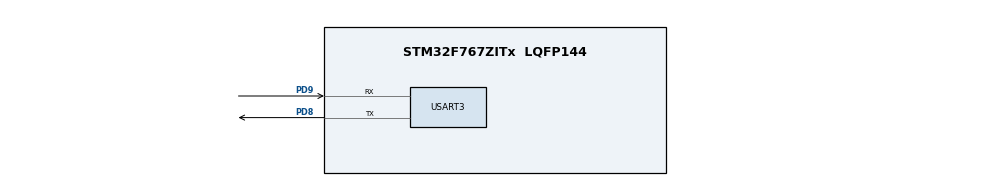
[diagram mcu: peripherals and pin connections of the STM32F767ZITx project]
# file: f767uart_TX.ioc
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Mcu.Family=STM32F7
PD9.Signal=USART3_RX
PD9.Mode=Asynchronous
ProjectManager.StackSize=0x400
USART3.VirtualMode-Asynchronous=VM_ASYNC
PA13.Signal=SYS_JTMS-SWDIO
ProjectManager.TargetToolchain=STM32CubeIDE
PD8.Signal=USART3_TX
RCC.USBFreq_Value=96000000
RCC.LSE_VALUE=32768
PD8.Mode=Asynchronous
RCC.HSE_VALUE=25000000
board=custom
RCC.VCOOutputFreq_Value=192000000
PA14.Mode=Serial_Wire
VP_SYS_VS_tim1.Mode=TIM1
PA13.Mode=Serial_Wire
Mcu.Name=STM32F767ZITx
Mcu.Package=LQFP144
NVIC.TimeBase=TIM1_UP_TIM10_IRQn
NVIC.TimeBaseIP=TIM1
PA14.Signal=SYS_JTCK-SWCLK
ProjectManager.HeapSize=0x200
NVIC.TIM1_UP_TIM10_IRQn=true\:0\:0\:false\:false\:true\:false\:true
RCC.HSI_VALUE=16000000
NVIC.PriorityGroup=NVIC_PRIORITYGROUP_4

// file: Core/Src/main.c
/* USER CODE BEGIN Header */
/**
  ******************************************************************************
  * @file           : main.c
  * @brief          : Main program body
  ******************************************************************************
  * @attention
  *
  * <h2><center>&copy; Copyright (c) 2022 STMicroelectronics.
  * All rights reserved.</center></h2>
  *
  * This software component is licensed by ST under BSD 3-Clause license,
  * the "License"; You may not use this file except in compliance with the
  * License. You may obtain a copy of the License at:
  *                        opensource.org/licenses/BSD-3-Clause
  *
  ******************************************************************************
  */
/* USER CODE END Header */
#include "main.h"

UART_HandleTypeDef huart3;

void SystemClock_Config(void);
static void MX_GPIO_Init(void);
static void MX_USART3_UART_Init(void);

int main(void)
{

  /* MCU Configuration--------------------------------------------------------*/

  /* Reset of all peripherals, Initializes the Flash interface and the Systick. */
  HAL_Init();

  /* Configure the system clock */
  SystemClock_Config();

  /* Initialize all configured peripherals */
  MX_GPIO_Init();
  MX_USART3_UART_Init();
  /* USER CODE BEGIN 2 */
  uint8_t buffer[] = "Hello from the board\r\n";
  /* USER CODE END 2 */

  /* Infinite loop */
  while (1)
  {
	  HAL_StatusTypeDef status = HAL_UART_Transmit(&huart3, buffer, sizeof(buffer), 100);
	  HAL_Delay(1000);
  }
}

void SystemClock_Config(void)
{
  RCC_OscInitTypeDef RCC_OscInitStruct = {0};
  RCC_ClkInitTypeDef RCC_ClkInitStruct = {0};
  RCC_PeriphCLKInitTypeDef PeriphClkInitStruct = {0};

  /** Configure the main internal regulator output voltage
  */
  __HAL_RCC_PWR_CLK_ENABLE();
  __HAL_PWR_VOLTAGESCALING_CONFIG(PWR_REGULATOR_VOLTAGE_SCALE3);
  /** Initializes the RCC Oscillators according to the specified parameters
  * in the RCC_OscInitTypeDef structure.
  */
  RCC_OscInitStruct.OscillatorType = RCC_OSCILLATORTYPE_HSI;
  RCC_OscInitStruct.HSIState = RCC_HSI_ON;
  RCC_OscInitStruct.HSICalibrationValue = RCC_HSICALIBRATION_DEFAULT;
  RCC_OscInitStruct.PLL.PLLState = RCC_PLL_NONE;
  if (HAL_RCC_OscConfig(&RCC_OscInitStruct) != HAL_OK)
  {
    Error_Handler();
  }
  /** Initializes the CPU, AHB and APB buses clocks
  */
  RCC_ClkInitStruct.ClockType = RCC_CLOCKTYPE_HCLK|RCC_CLOCKTYPE_SYSCLK
                              |RCC_CLOCKTYPE_PCLK1|RCC_CLOCKTYPE_PCLK2;
  RCC_ClkInitStruct.SYSCLKSource = RCC_SYSCLKSOURCE_HSI;
  RCC_ClkInitStruct.AHBCLKDivider = RCC_SYSCLK_DIV1;
  RCC_ClkInitStruct.APB1CLKDivider = RCC_HCLK_DIV1;
  RCC_ClkInitStruct.APB2CLKDivider = RCC_HCLK_DIV1;

  if (HAL_RCC_ClockConfig(&RCC_ClkInitStruct, FLASH_LATENCY_0) != HAL_OK)
  {
    Error_Handler();
  }
  PeriphClkInitStruct.PeriphClockSelection = RCC_PERIPHCLK_USART3;
  PeriphClkInitStruct.Usart3ClockSelection = RCC_USART3CLKSOURCE_PCLK1;
  if (HAL_RCCEx_PeriphCLKConfig(&PeriphClkInitStruct) != HAL_OK)
  {
    Error_Handler();
  }
}

static void MX_USART3_UART_Init(void)
{

  huart3.Instance = USART3;
  huart3.Init.BaudRate = 115200;
  huart3.Init.WordLength = UART_WORDLENGTH_8B;
  huart3.Init.StopBits = UART_STOPBITS_1;
  huart3.Init.Parity = UART_PARITY_NONE;
  huart3.Init.Mode = UART_MODE_TX_RX;
  huart3.Init.HwFlowCtl = UART_HWCONTROL_NONE;
  huart3.Init.OverSampling = UART_OVERSAMPLING_16;
  huart3.Init.OneBitSampling = UART_ONE_BIT_SAMPLE_DISABLE;
  huart3.AdvancedInit.AdvFeatureInit = UART_ADVFEATURE_NO_INIT;
  if (HAL_UART_Init(&huart3) != HAL_OK)
  {
    Error_Handler();
  }

}

static void MX_GPIO_Init(void)
{

  /* GPIO Ports Clock Enable */
  __HAL_RCC_GPIOD_CLK_ENABLE();
  __HAL_RCC_GPIOA_CLK_ENABLE();

}

 /**
  * @brief  Period elapsed callback in non blocking mode
  * @note   This function is called  when TIM1 interrupt took place, inside
  * HAL_TIM_IRQHandler(). It makes a direct call to HAL_IncTick() to increment
  * a global variable "uwTick" used as application time base.
  * @param  htim : TIM handle
  * @retval None
  */
void HAL_TIM_PeriodElapsedCallback(TIM_HandleTypeDef *htim)
{
  if (htim->Instance == TIM1) {
    HAL_IncTick();
  }
}

void Error_Handler(void)
{
  __disable_irq();
  while (1)
  {
  }
}

/************************ (C) COPYRIGHT STMicroelectronics *****END OF FILE****/
